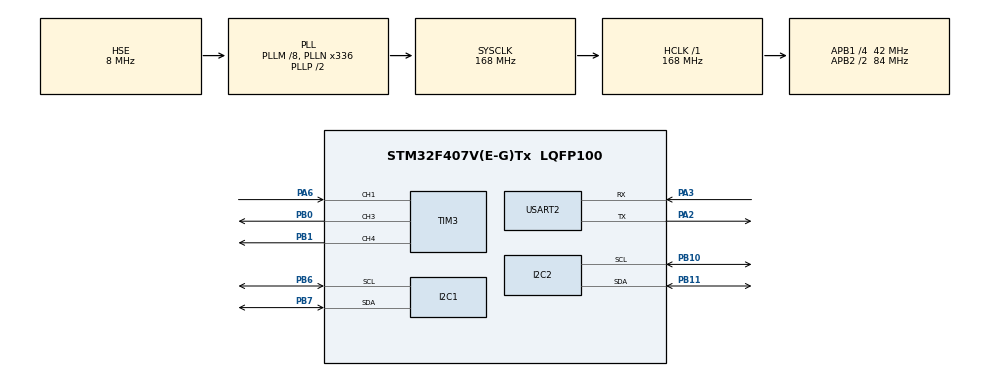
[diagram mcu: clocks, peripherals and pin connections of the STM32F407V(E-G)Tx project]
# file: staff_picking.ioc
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Mcu.Family=STM32F4
Mcu.Name=STM32F407V(E-G)Tx
Mcu.Package=LQFP100
NVIC.PriorityGroup=NVIC_PRIORITYGROUP_0
PA13.Mode=Serial_Wire
PA13.Signal=SYS_JTMS-SWDIO
PA14.Mode=Serial_Wire
PA14.Signal=SYS_JTCK-SWCLK
PA2.Mode=Asynchronous
PA2.Signal=USART2_TX
PA3.Mode=Asynchronous
PA3.Signal=USART2_RX
PA6.Signal=S_TIM3_CH1
PB0.Signal=S_TIM3_CH3
PB1.Signal=S_TIM3_CH4
PB10.Mode=I2C
PB10.Signal=I2C2_SCL
PB11.Mode=I2C
PB11.Signal=I2C2_SDA
PB6.Mode=I2C
PB6.Signal=I2C1_SCL
PB7.Mode=I2C
PB7.Signal=I2C1_SDA
PC14-OSC32_IN.Mode=LSE-External-Oscillator
PC14-OSC32_IN.Signal=RCC_OSC32_IN
PC15-OSC32_OUT.Mode=LSE-External-Oscillator
PC15-OSC32_OUT.Signal=RCC_OSC32_OUT
PH0-OSC_IN.Mode=HSE-External-Oscillator
PH0-OSC_IN.Signal=RCC_OSC_IN
PH1-OSC_OUT.Mode=HSE-External-Oscillator
PH1-OSC_OUT.Signal=RCC_OSC_OUT
ProjectManager.HeapSize=0x200
ProjectManager.StackSize=0x400
ProjectManager.TargetToolchain=STM32CubeIDE
RCC.48MHZClocksFreq_Value=48000000
RCC.AHBFreq_Value=168000000
RCC.APB1CLKDivider=RCC_HCLK_DIV4
RCC.APB1Freq_Value=42000000
RCC.APB1TimFreq_Value=84000000
RCC.APB2CLKDivider=RCC_HCLK_DIV2
RCC.APB2Freq_Value=84000000
RCC.APB2TimFreq_Value=168000000
RCC.CortexFreq_Value=168000000
RCC.HCLKFreq_Value=168000000
RCC.HSE_VALUE=8000000
RCC.HSI_VALUE=16000000
RCC.PLLM=8
RCC.PLLN=336
RCC.PLLQ=7
RCC.PLLSourceVirtual=RCC_PLLSOURCE_HSE
RCC.SYSCLKFreq_VALUE=168000000
RCC.SYSCLKSource=RCC_SYSCLKSOURCE_PLLCLK
RCC.VCOOutputFreq_Value=336000000
SH.S_TIM3_CH1.0=TIM3_CH1,Input_Capture1_from_TI1
SH.S_TIM3_CH3.0=TIM3_CH3,PWM Generation3 CH3
SH.S_TIM3_CH4.0=TIM3_CH4,PWM Generation4 CH4
TIM3.Channel-Input_Capture1_from_TI1=TIM_CHANNEL_1
TIM3.Channel-PWM\ Generation3\ CH3=TIM_CHANNEL_3
TIM3.Channel-PWM\ Generation4\ CH4=TIM_CHANNEL_4
USART2.VirtualMode=VM_ASYNC
VP_TIM3_VS_ClockSourceINT.Mode=Internal
board=STM32F407G-DISC1

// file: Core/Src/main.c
/* USER CODE BEGIN Header */
/**
  ******************************************************************************
  * @file           : main.c
  * @brief          : Main program body
  ******************************************************************************
  * @attention
  *
  * Copyright (c) 2026 STMicroelectronics.
  * All rights reserved.
  *
  * This software is licensed under terms that can be found in the LICENSE file
  * in the root directory of this software component.
  * If no LICENSE file comes with this software, it is provided AS-IS.
  *
  ******************************************************************************
  */
/* USER CODE END Header */
#include "main.h"
#include "String.h"
#include "BTS7960.h"
#include "PCA9685.h"
/* USER CODE BEGIN Includes */
BTS b1;
PCA_t pca1;
/* USER CODE END Includes */

I2C_HandleTypeDef hi2c1;
I2C_HandleTypeDef hi2c2;

TIM_HandleTypeDef htim3;

UART_HandleTypeDef huart2;

/* USER CODE BEGIN PV */
int8_t psdata[3] = {0};

/* USER CODE END PV */

void SystemClock_Config(void);
static void MX_GPIO_Init(void);
static void MX_I2C1_Init(void);
static void MX_I2C2_Init(void);
static void MX_USART2_UART_Init(void);
static void MX_TIM3_Init(void);

int main(void)
{

  /* MCU Configuration--------------------------------------------------------*/

  /* Reset of all peripherals, Initializes the Flash interface and the Systick. */
  HAL_Init();

  /* Configure the system clock */
  SystemClock_Config();

  /* Initialize all configured peripherals */
  MX_GPIO_Init();
  MX_I2C1_Init();
  MX_I2C2_Init();
  MX_USART2_UART_Init();
  MX_TIM3_Init();
  /* USER CODE BEGIN 2 */
  PCA_init(&pca1,&hi2c2, 50);
  InitBTS(&b1 , &htim3, TIM_CHANNEL_3,&htim3, TIM_CHANNEL_4, 1,1000);

  /* USER CODE END 2 */

  /* Infinite loop */
  while (1)
  {
	  char buffer[20];

	  	  HAL_I2C_Master_Receive(&hi2c1, 0x04 << 1, (uint8_t*)psdata, sizeof(psdata), 100);
	  	  for (uint8_t i = 0; i < sizeof(psdata); i++)
	  	  {
	  	      sprintf(buffer, "%d ", psdata[i]);
	  	      HAL_UART_Transmit(&huart2, (uint8_t*)buffer, strlen(buffer), HAL_MAX_DELAY);
	  	  }

	  	  char newline[] = "\r\n";
	  	  HAL_UART_Transmit(&huart2, (uint8_t*)newline, strlen(newline), HAL_MAX_DELAY);

	  	  if(psdata[0] > 80){
	  		RotateMotor(&b1,30);
	  	  }

	  	  if(psdata[0] > -80){
	  		RotateMotor(&b1,-30);

	      }

	  	  if(psdata[1]==80){
	  		rotate(&pca1 ,2, 90);
	  	  }

	  	  if(psdata[1]==-80){
	  		rotate(&pca1 ,2, 0);
	  	  }

	  	  if(psdata[2]==80){
	  		rotate(&pca1 ,3, 90);
	  	  }

	  	  if(psdata[2]==-80){
	  		rotate(&pca1 ,3, 0);

	      }

  }
}

void SystemClock_Config(void)
{
  RCC_OscInitTypeDef RCC_OscInitStruct = {0};
  RCC_ClkInitTypeDef RCC_ClkInitStruct = {0};

  /** Configure the main internal regulator output voltage
  */
  __HAL_RCC_PWR_CLK_ENABLE();
  __HAL_PWR_VOLTAGESCALING_CONFIG(PWR_REGULATOR_VOLTAGE_SCALE1);

  /** Initializes the RCC Oscillators according to the specified parameters
  * in the RCC_OscInitTypeDef structure.
  */
  RCC_OscInitStruct.OscillatorType = RCC_OSCILLATORTYPE_HSE;
  RCC_OscInitStruct.HSEState = RCC_HSE_ON;
  RCC_OscInitStruct.PLL.PLLState = RCC_PLL_ON;
  RCC_OscInitStruct.PLL.PLLSource = RCC_PLLSOURCE_HSE;
  RCC_OscInitStruct.PLL.PLLM = 8;
  RCC_OscInitStruct.PLL.PLLN = 336;
  RCC_OscInitStruct.PLL.PLLP = RCC_PLLP_DIV2;
  RCC_OscInitStruct.PLL.PLLQ = 7;
  if (HAL_RCC_OscConfig(&RCC_OscInitStruct) != HAL_OK)
  {
    Error_Handler();
  }

  /** Initializes the CPU, AHB and APB buses clocks
  */
  RCC_ClkInitStruct.ClockType = RCC_CLOCKTYPE_HCLK|RCC_CLOCKTYPE_SYSCLK
                              |RCC_CLOCKTYPE_PCLK1|RCC_CLOCKTYPE_PCLK2;
  RCC_ClkInitStruct.SYSCLKSource = RCC_SYSCLKSOURCE_PLLCLK;
  RCC_ClkInitStruct.AHBCLKDivider = RCC_SYSCLK_DIV1;
  RCC_ClkInitStruct.APB1CLKDivider = RCC_HCLK_DIV4;
  RCC_ClkInitStruct.APB2CLKDivider = RCC_HCLK_DIV2;

  if (HAL_RCC_ClockConfig(&RCC_ClkInitStruct, FLASH_LATENCY_5) != HAL_OK)
  {
    Error_Handler();
  }
}

static void MX_I2C1_Init(void)
{

  hi2c1.Instance = I2C1;
  hi2c1.Init.ClockSpeed = 100000;
  hi2c1.Init.DutyCycle = I2C_DUTYCYCLE_2;
  hi2c1.Init.OwnAddress1 = 0;
  hi2c1.Init.AddressingMode = I2C_ADDRESSINGMODE_7BIT;
  hi2c1.Init.DualAddressMode = I2C_DUALADDRESS_DISABLE;
  hi2c1.Init.OwnAddress2 = 0;
  hi2c1.Init.GeneralCallMode = I2C_GENERALCALL_DISABLE;
  hi2c1.Init.NoStretchMode = I2C_NOSTRETCH_DISABLE;
  if (HAL_I2C_Init(&hi2c1) != HAL_OK)
  {
    Error_Handler();
  }

}

static void MX_I2C2_Init(void)
{

  hi2c2.Instance = I2C2;
  hi2c2.Init.ClockSpeed = 100000;
  hi2c2.Init.DutyCycle = I2C_DUTYCYCLE_2;
  hi2c2.Init.OwnAddress1 = 0;
  hi2c2.Init.AddressingMode = I2C_ADDRESSINGMODE_7BIT;
  hi2c2.Init.DualAddressMode = I2C_DUALADDRESS_DISABLE;
  hi2c2.Init.OwnAddress2 = 0;
  hi2c2.Init.GeneralCallMode = I2C_GENERALCALL_DISABLE;
  hi2c2.Init.NoStretchMode = I2C_NOSTRETCH_DISABLE;
  if (HAL_I2C_Init(&hi2c2) != HAL_OK)
  {
    Error_Handler();
  }

}

static void MX_TIM3_Init(void)
{

  TIM_ClockConfigTypeDef sClockSourceConfig = {0};
  TIM_MasterConfigTypeDef sMasterConfig = {0};
  TIM_OC_InitTypeDef sConfigOC = {0};

  htim3.Instance = TIM3;
  htim3.Init.Prescaler = 0;
  htim3.Init.CounterMode = TIM_COUNTERMODE_UP;
  htim3.Init.Period = 65535;
  htim3.Init.ClockDivision = TIM_CLOCKDIVISION_DIV1;
  htim3.Init.AutoReloadPreload = TIM_AUTORELOAD_PRELOAD_DISABLE;
  if (HAL_TIM_Base_Init(&htim3) != HAL_OK)
  {
    Error_Handler();
  }
  sClockSourceConfig.ClockSource = TIM_CLOCKSOURCE_INTERNAL;
  if (HAL_TIM_ConfigClockSource(&htim3, &sClockSourceConfig) != HAL_OK)
  {
    Error_Handler();
  }
  if (HAL_TIM_PWM_Init(&htim3) != HAL_OK)
  {
    Error_Handler();
  }
  sMasterConfig.MasterOutputTrigger = TIM_TRGO_RESET;
  sMasterConfig.MasterSlaveMode = TIM_MASTERSLAVEMODE_DISABLE;
  if (HAL_TIMEx_MasterConfigSynchronization(&htim3, &sMasterConfig) != HAL_OK)
  {
    Error_Handler();
  }
  sConfigOC.OCMode = TIM_OCMODE_PWM1;
  sConfigOC.Pulse = 0;
  sConfigOC.OCPolarity = TIM_OCPOLARITY_HIGH;
  sConfigOC.OCFastMode = TIM_OCFAST_DISABLE;
  if (HAL_TIM_PWM_ConfigChannel(&htim3, &sConfigOC, TIM_CHANNEL_1) != HAL_OK)
  {
    Error_Handler();
  }
  HAL_TIM_MspPostInit(&htim3);

}

static void MX_USART2_UART_Init(void)
{

  huart2.Instance = USART2;
  huart2.Init.BaudRate = 115200;
  huart2.Init.WordLength = UART_WORDLENGTH_8B;
  huart2.Init.StopBits = UART_STOPBITS_1;
  huart2.Init.Parity = UART_PARITY_NONE;
  huart2.Init.Mode = UART_MODE_TX_RX;
  huart2.Init.HwFlowCtl = UART_HWCONTROL_NONE;
  huart2.Init.OverSampling = UART_OVERSAMPLING_16;
  if (HAL_UART_Init(&huart2) != HAL_OK)
  {
    Error_Handler();
  }

}

static void MX_GPIO_Init(void)
{

  /* GPIO Ports Clock Enable */
  __HAL_RCC_GPIOC_CLK_ENABLE();
  __HAL_RCC_GPIOH_CLK_ENABLE();
  __HAL_RCC_GPIOA_CLK_ENABLE();
  __HAL_RCC_GPIOB_CLK_ENABLE();

}

void Error_Handler(void)
{
  __disable_irq();
  while (1)
  {
  }
}
